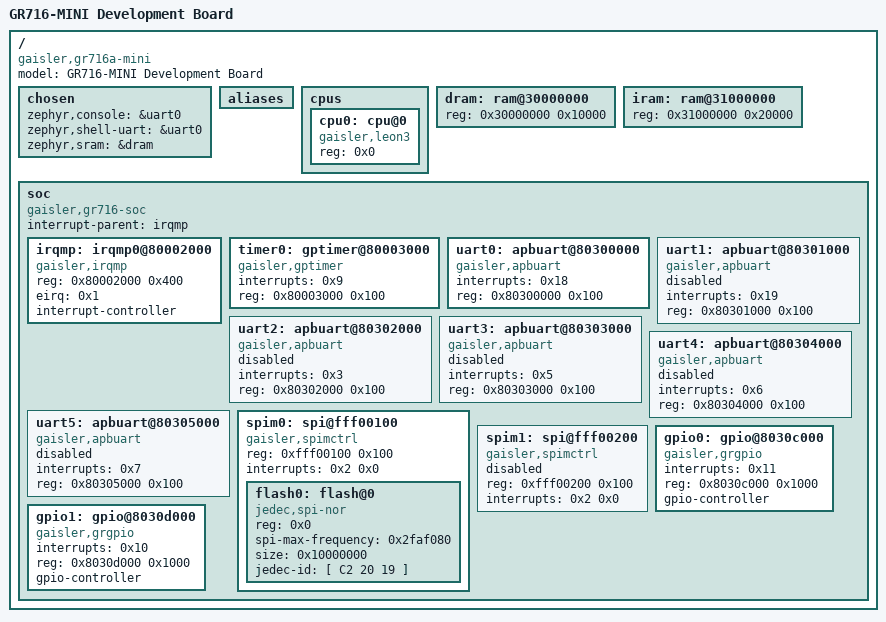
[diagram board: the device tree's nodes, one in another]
/dts-v1/;

/* node '/' defined in zephyr/dts/common/skeleton.dtsi:9 */
/ {
	#address-cells = < 0x1 >;               /* in zephyr/dts/common/skeleton.dtsi:10 */
	#size-cells = < 0x1 >;                  /* in zephyr/dts/common/skeleton.dtsi:11 */
	model = "GR716-MINI Development Board"; /* in zephyr/boards/gaisler/gr716a_mini/gr716a_mini.dts:13 */
	compatible = "gaisler,gr716a-mini";     /* in zephyr/boards/gaisler/gr716a_mini/gr716a_mini.dts:14 */

	/* node '/chosen' defined in zephyr/dts/common/skeleton.dtsi:13 */
	chosen {
		zephyr,console = &uart0;    /* in zephyr/boards/gaisler/gr716a_mini/gr716a_mini.dts:17 */
		zephyr,shell-uart = &uart0; /* in zephyr/boards/gaisler/gr716a_mini/gr716a_mini.dts:18 */
		zephyr,sram = &dram;        /* in zephyr/boards/gaisler/gr716a_mini/gr716a_mini.dts:19 */
	};

	/* node '/aliases' defined in zephyr/dts/common/skeleton.dtsi:15 */
	aliases {
	};

	/* node '/cpus' defined in zephyr/dts/sparc/gaisler/gr716a.dtsi:11 */
	cpus {
		#address-cells = < 0x1 >; /* in zephyr/dts/sparc/gaisler/gr716a.dtsi:12 */
		#size-cells = < 0x0 >;    /* in zephyr/dts/sparc/gaisler/gr716a.dtsi:13 */

		/* node '/cpus/cpu@0' defined in zephyr/dts/sparc/gaisler/gr716a.dtsi:15 */
		cpu0: cpu@0 {
			compatible = "gaisler,leon3"; /* in zephyr/dts/sparc/gaisler/gr716a.dtsi:16 */
			reg = < 0x0 >;                /* in zephyr/dts/sparc/gaisler/gr716a.dtsi:17 */
		};
	};

	/* node '/ram@30000000' defined in zephyr/dts/sparc/gaisler/gr716a.dtsi:21 */
	dram: ram@30000000 {
		reg = < 0x30000000 0x10000 >; /* in zephyr/dts/sparc/gaisler/gr716a.dtsi:23 */
	};

	/* node '/ram@31000000' defined in zephyr/dts/sparc/gaisler/gr716a.dtsi:26 */
	iram: ram@31000000 {
		reg = < 0x31000000 0x20000 >; /* in zephyr/dts/sparc/gaisler/gr716a.dtsi:28 */
	};

	/* node '/soc' defined in zephyr/dts/sparc/gaisler/gr716a.dtsi:31 */
	soc {
		#address-cells = < 0x1 >;         /* in zephyr/dts/sparc/gaisler/gr716a.dtsi:32 */
		#size-cells = < 0x1 >;            /* in zephyr/dts/sparc/gaisler/gr716a.dtsi:33 */
		compatible = "gaisler,gr716-soc",
		             "simple-bus";        /* in zephyr/dts/sparc/gaisler/gr716a.dtsi:34 */
		ranges;                           /* in zephyr/dts/sparc/gaisler/gr716a.dtsi:35 */
		interrupt-parent = < &irqmp >;    /* in zephyr/dts/sparc/gaisler/gr716a.dtsi:36 */

		/* node '/soc/irqmp0@80002000' defined in zephyr/dts/sparc/gaisler/gr716a.dtsi:38 */
		irqmp: irqmp0@80002000 {
			compatible = "gaisler,irqmp"; /* in zephyr/dts/sparc/gaisler/gr716a.dtsi:39 */
			reg = < 0x80002000 0x400 >;   /* in zephyr/dts/sparc/gaisler/gr716a.dtsi:40 */
			eirq = < 0x1 >;               /* in zephyr/dts/sparc/gaisler/gr716a.dtsi:41 */
			interrupt-controller;         /* in zephyr/dts/sparc/gaisler/gr716a.dtsi:42 */
			#interrupt-cells = < 0x1 >;   /* in zephyr/dts/sparc/gaisler/gr716a.dtsi:43 */
			phandle = < 0x1 >;            /* in zephyr/dts/sparc/gaisler/gr716a.dtsi:36 */
		};

		/* node '/soc/gptimer@80003000' defined in zephyr/dts/sparc/gaisler/gr716a.dtsi:46 */
		timer0: gptimer@80003000 {
			compatible = "gaisler,gptimer"; /* in zephyr/dts/sparc/gaisler/gr716a.dtsi:47 */
			interrupts = < 0x9 >;           /* in zephyr/dts/sparc/gaisler/gr716a.dtsi:48 */
			reg = < 0x80003000 0x100 >;     /* in zephyr/dts/sparc/gaisler/gr716a.dtsi:49 */
		};

		/* node '/soc/apbuart@80300000' defined in zephyr/dts/sparc/gaisler/gr716a.dtsi:52 */
		uart0: apbuart@80300000 {
			compatible = "gaisler,apbuart"; /* in zephyr/dts/sparc/gaisler/gr716a.dtsi:53 */
			interrupts = < 0x18 >;          /* in zephyr/dts/sparc/gaisler/gr716a.dtsi:54 */
			reg = < 0x80300000 0x100 >;     /* in zephyr/dts/sparc/gaisler/gr716a.dtsi:55 */
			status = "okay";                /* in zephyr/boards/gaisler/gr716a_mini/gr716a_mini.dts:24 */
		};

		/* node '/soc/apbuart@80301000' defined in zephyr/dts/sparc/gaisler/gr716a.dtsi:59 */
		uart1: apbuart@80301000 {
			compatible = "gaisler,apbuart"; /* in zephyr/dts/sparc/gaisler/gr716a.dtsi:60 */
			interrupts = < 0x19 >;          /* in zephyr/dts/sparc/gaisler/gr716a.dtsi:61 */
			reg = < 0x80301000 0x100 >;     /* in zephyr/dts/sparc/gaisler/gr716a.dtsi:62 */
			status = "disabled";            /* in zephyr/dts/sparc/gaisler/gr716a.dtsi:63 */
		};

		/* node '/soc/apbuart@80302000' defined in zephyr/dts/sparc/gaisler/gr716a.dtsi:66 */
		uart2: apbuart@80302000 {
			compatible = "gaisler,apbuart"; /* in zephyr/dts/sparc/gaisler/gr716a.dtsi:67 */
			interrupts = < 0x3 >;           /* in zephyr/dts/sparc/gaisler/gr716a.dtsi:68 */
			reg = < 0x80302000 0x100 >;     /* in zephyr/dts/sparc/gaisler/gr716a.dtsi:69 */
			status = "disabled";            /* in zephyr/dts/sparc/gaisler/gr716a.dtsi:70 */
		};

		/* node '/soc/apbuart@80303000' defined in zephyr/dts/sparc/gaisler/gr716a.dtsi:73 */
		uart3: apbuart@80303000 {
			compatible = "gaisler,apbuart"; /* in zephyr/dts/sparc/gaisler/gr716a.dtsi:74 */
			interrupts = < 0x5 >;           /* in zephyr/dts/sparc/gaisler/gr716a.dtsi:75 */
			reg = < 0x80303000 0x100 >;     /* in zephyr/dts/sparc/gaisler/gr716a.dtsi:76 */
			status = "disabled";            /* in zephyr/dts/sparc/gaisler/gr716a.dtsi:77 */
		};

		/* node '/soc/apbuart@80304000' defined in zephyr/dts/sparc/gaisler/gr716a.dtsi:80 */
		uart4: apbuart@80304000 {
			compatible = "gaisler,apbuart"; /* in zephyr/dts/sparc/gaisler/gr716a.dtsi:81 */
			interrupts = < 0x6 >;           /* in zephyr/dts/sparc/gaisler/gr716a.dtsi:82 */
			reg = < 0x80304000 0x100 >;     /* in zephyr/dts/sparc/gaisler/gr716a.dtsi:83 */
			status = "disabled";            /* in zephyr/dts/sparc/gaisler/gr716a.dtsi:84 */
		};

		/* node '/soc/apbuart@80305000' defined in zephyr/dts/sparc/gaisler/gr716a.dtsi:87 */
		uart5: apbuart@80305000 {
			compatible = "gaisler,apbuart"; /* in zephyr/dts/sparc/gaisler/gr716a.dtsi:88 */
			interrupts = < 0x7 >;           /* in zephyr/dts/sparc/gaisler/gr716a.dtsi:89 */
			reg = < 0x80305000 0x100 >;     /* in zephyr/dts/sparc/gaisler/gr716a.dtsi:90 */
			status = "disabled";            /* in zephyr/dts/sparc/gaisler/gr716a.dtsi:91 */
		};

		/* node '/soc/spi@fff00100' defined in zephyr/dts/sparc/gaisler/gr716a.dtsi:94 */
		spim0: spi@fff00100 {
			compatible = "gaisler,spimctrl"; /* in zephyr/dts/sparc/gaisler/gr716a.dtsi:95 */
			reg = < 0xfff00100 0x100 >;      /* in zephyr/dts/sparc/gaisler/gr716a.dtsi:96 */
			interrupts = < 0x2 0x0 >;        /* in zephyr/dts/sparc/gaisler/gr716a.dtsi:97 */
			#address-cells = < 0x1 >;        /* in zephyr/dts/sparc/gaisler/gr716a.dtsi:98 */
			#size-cells = < 0x0 >;           /* in zephyr/dts/sparc/gaisler/gr716a.dtsi:99 */
			status = "okay";                 /* in zephyr/boards/gaisler/gr716a_mini/gr716a_mini.dts:28 */

			/* node '/soc/spi@fff00100/flash@0' defined in zephyr/boards/gaisler/gr716a_mini/gr716a_mini.dts:31 */
			flash0: flash@0 {
				compatible = "jedec,spi-nor";      /* in zephyr/boards/gaisler/gr716a_mini/gr716a_mini.dts:32 */
				reg = < 0x0 >;                     /* in zephyr/boards/gaisler/gr716a_mini/gr716a_mini.dts:33 */
				spi-max-frequency = < 0x2faf080 >; /* in zephyr/boards/gaisler/gr716a_mini/gr716a_mini.dts:34 */
				size = < 0x10000000 >;             /* in zephyr/boards/gaisler/gr716a_mini/gr716a_mini.dts:35 */
				jedec-id = [ C2 20 19 ];           /* in zephyr/boards/gaisler/gr716a_mini/gr716a_mini.dts:36 */
			};
		};

		/* node '/soc/spi@fff00200' defined in zephyr/dts/sparc/gaisler/gr716a.dtsi:103 */
		spim1: spi@fff00200 {
			compatible = "gaisler,spimctrl"; /* in zephyr/dts/sparc/gaisler/gr716a.dtsi:104 */
			reg = < 0xfff00200 0x100 >;      /* in zephyr/dts/sparc/gaisler/gr716a.dtsi:105 */
			interrupts = < 0x2 0x0 >;        /* in zephyr/dts/sparc/gaisler/gr716a.dtsi:106 */
			#address-cells = < 0x1 >;        /* in zephyr/dts/sparc/gaisler/gr716a.dtsi:107 */
			#size-cells = < 0x0 >;           /* in zephyr/dts/sparc/gaisler/gr716a.dtsi:108 */
			status = "disabled";             /* in zephyr/dts/sparc/gaisler/gr716a.dtsi:109 */
		};

		/* node '/soc/gpio@8030c000' defined in zephyr/dts/sparc/gaisler/gr716a.dtsi:112 */
		gpio0: gpio@8030c000 {
			interrupts = < 0x11 >;         /* in zephyr/dts/sparc/gaisler/gr716a.dtsi:113 */
			reg = < 0x8030c000 0x1000 >;   /* in zephyr/dts/sparc/gaisler/gr716a.dtsi:114 */
			compatible = "gaisler,grgpio"; /* in zephyr/dts/sparc/gaisler/gr716a.dtsi:115 */
			gpio-controller;               /* in zephyr/dts/sparc/gaisler/gr716a.dtsi:116 */
			#gpio-cells = < 0x2 >;         /* in zephyr/dts/sparc/gaisler/gr716a.dtsi:117 */
			status = "okay";               /* in zephyr/boards/gaisler/gr716a_mini/gr716a_mini.dts:41 */
		};

		/* node '/soc/gpio@8030d000' defined in zephyr/dts/sparc/gaisler/gr716a.dtsi:121 */
		gpio1: gpio@8030d000 {
			interrupts = < 0x10 >;         /* in zephyr/dts/sparc/gaisler/gr716a.dtsi:122 */
			reg = < 0x8030d000 0x1000 >;   /* in zephyr/dts/sparc/gaisler/gr716a.dtsi:123 */
			compatible = "gaisler,grgpio"; /* in zephyr/dts/sparc/gaisler/gr716a.dtsi:124 */
			gpio-controller;               /* in zephyr/dts/sparc/gaisler/gr716a.dtsi:125 */
			#gpio-cells = < 0x2 >;         /* in zephyr/dts/sparc/gaisler/gr716a.dtsi:126 */
			status = "okay";               /* in zephyr/boards/gaisler/gr716a_mini/gr716a_mini.dts:45 */
		};
	};
};
